# I94100_v1_3 register map
File version: 1.0
Registers are 32-bit, read-write, reset 0x0 unless marked. A register's access mark holds for its fields unless they carry their own. Offsets are from the block's base; [hi:lo] are bit positions; {n}, {i} and the like mark numbered series.

## DMIC — DMIC Register Map
Base 0x40063000
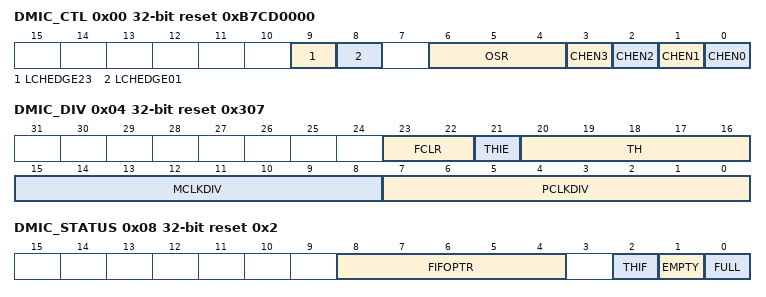
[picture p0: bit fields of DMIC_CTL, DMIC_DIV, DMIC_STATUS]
0x00 DMIC_CTL reset 0xB7CD0000 — DMIC Control Register
  [9] LCHEDGE23 — Channel 23 Data Latch Edge. The data of DMIC channel 2 and channel 3 is latched on DMIC_DATA1 pin. This bit is used to select the data of DMIC channel 2 and channel 3 is latched on rising or falling edge of DMIC_CLK (DMIC bus clock).
    0=The data of channel 2 is latched on falling edge of DMIC_CLK. The data of channel 3 is latched on rising edge of DMIC_CLK; 1=The data of channel 2 is latched on rising edge of DMIC_CLK. The data of channel 3 is latched on falling edge of DMIC_CLK
  [8] LCHEDGE01 — Channel 01 Data Latch Edge. The data of DMIC channel 0 and channel 1 is latched on DMIC_DATA0 pin. This bit is used to select the data of DMIC channel 0 and channel 1 is latched on rising or falling edge of DMIC_CLK (DMIC bus clock).
    0=The data of channel 0 is latched on falling edge of DMIC_CLK. The data of channel 1 is latched on rising edge of DMIC_CLK; 1=The data of channel 0 is latched on rising edge of DMIC_CLK. The data of channel 1 is latched on falling edge of DMIC_CLK
  [6:4] OSR — OSR Setting
    0=Down sample 32; 1=Down sample 64; 2=Down sample 128; 3=Down sample 256; 4=Down sample 100 or 50
  [n] CHEN{n} (n=0..3) — Channel {n} Enable Bit. Set this bit to 1 to enable DMIC channel {n} operation.
    0=Channel {n} Disabled; 1=Channel {n} Enabled
0x04 DMIC_DIV reset 0x307 — DMIC Clock Divider Register
  [23:22] FCLR — FIFO Clear. Note 1: To clear the FIFO, need to write FCLR (DMIC_DIV[23:22]) to 11b, and can read the EMPTY (DMIC_STATUS[1]) bit to make sure that the FIFO has been cleared. Note 2: This field is auto cleared by hardware.
    3=Clear the FIFO
  [21] THIE — FIFO Threshold Interrupt
    0=FIFO threshold interrupt Disabled; 1=FIFO threshold interrupt Enabled
  [20:16] TH — FIFO Threshold Level. If the valid data count of the FIFO data buffer is more than or equal to TH (DMIC_DIV[20:16]) setting, the THIF (DMIC_STATUS[2]) bit will set to 1, else the THIF (DMIC_STATUS[2]) bit will be cleared to 0.
  [15:8] MCLKDIV — Divider to generate the DMIC Bus Clock. The value in this field is the frequency divider for generating the DMIC bus clock. The frequency is obtained according to the following equation. where F_DMIC_MCLK is the frequency of DMIC working main clock (DMIC_MCLK) and F_DMIC_CLK is the frequency of DMIC bus clock (DMIC_CLK).
  [7:0] PCLKDIV — Divider to generate the DMIC Working Main Clock. The value in this field is the frequency divider for generating the DMIC working main clock. The frequency is obtained according to the following equation. where F_DMIC_CLK_SRC is the frequency of DMIC module clock source, which is defined in the clock control register DMICSEL (CLK_CLKSEL2[11:10]) and F_DMIC_MCLK is the frequency of DMIC working main clock (DMIC_MCLK).
0x08 DMIC_STATUS ro reset 0x2
  [8:4] FIFOPTR — FIFO Pointer (Read Only). The FULL (DMIC_STATUS[0]) and FIFOPTR (DMIC_STATUS[8:4]) indicates the field that the valid data count within the DMIC FIFO buffer. The maximum value shown in FIFOPTR (DMIC_STATUS[8:4]) is 31. When the using level of DMIC FIFO buffer equal to 32, The FULL (DMIC_STATUS[0]) is set to 1.
  [2] THIF — FIFO Threshold Interrupt Status (Read Only)
    0=The valid data count within the FIFO data buffer is less than the setting value of TH (DMIC_DIV[20:16]); 1=The valid data count within the FIFO data buffer is more than or equal to the setting value of TH (DMIC_DIV[20:16])
  [1] EMPTY — FIFO Empty Indicator (Read Only)
    0=FIFO is not empty; 1=FIFO is empty
  [0] FULL — FIFO Full Indicator (Read Only)
    0=FIFO is not full; 1=FIFO is full
0x0C DMIC_PDMACTL — DMIC PDMA Control Register
  [0] PDMAEN — PDMA Transfer Enable Bit
    0=PDMA data transfer Disabled; 1=PDMA data transfer Enabled
0x10 DMIC_FIFO wo — DMIC FIFO Data Output Register
  [23:0] FIFO — FIFO Data Output Register. DMIC contains 32 words (32x32 bit) data buffer for data receive. A read to this register pushes data out from FIFO data buffer and decrements the read pointer. This is the address that PDMA reads audio data from. The remaining data word number is indicated by FIFOPTR (DMIC_STATUS[8:4]).
